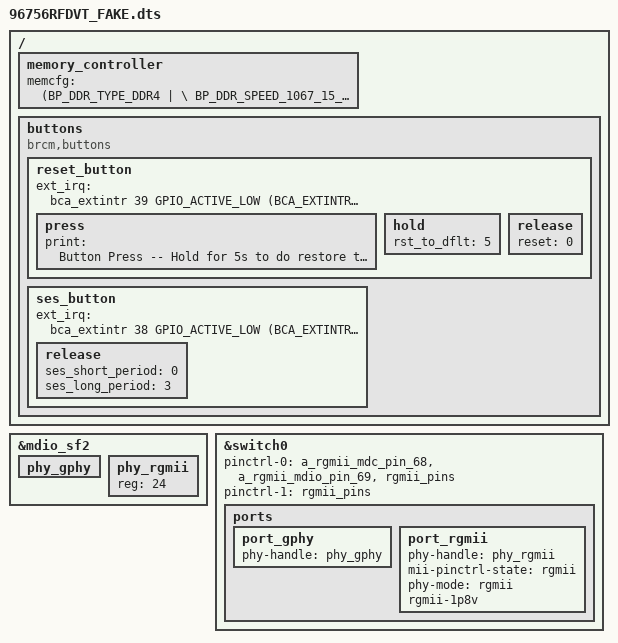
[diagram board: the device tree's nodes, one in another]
#include "6756.dtsi"

/ {
	memory_controller {
		memcfg = <(BP_DDR_TYPE_DDR4           | \
			BP_DDR_SPEED_1067_15_15_15 | \
			BP_DDR_TOTAL_SIZE_2048MB   | \
			BP_DDR_DEVICE_WIDTH_8      | \
			BP_DDR_TOTAL_WIDTH_16BIT   | \
			BP_DDR_6756_DEFAULT          | \
			BP_DDR_CONFIG_DEBUG)>;
	};

	buttons {
		compatible = "brcm,buttons";
		reset_button {
			ext_irq = <&bca_extintr 39 GPIO_ACTIVE_LOW (BCA_EXTINTR_TYPE_LOW_LEVEL | BCA_EXTINTR_TYPE_SENSE_EDGE)>;
			press {
				print = "Button Press -- Hold for 5s to do restore to default";
			};
			hold {
				rst_to_dflt = <5>;
			};
			release {
				reset = <0>;
			};	
		};
		ses_button {
			ext_irq = <&bca_extintr 38 GPIO_ACTIVE_LOW (BCA_EXTINTR_TYPE_LOW_LEVEL | BCA_EXTINTR_TYPE_SENSE_EDGE)>;
			release {
				ses_short_period = <0>;
				ses_long_period = <3>;
			};
		};	
	};
};


&mdio_sf2 {
   /* Port PHY mapping:
        port_imp -8#0- port_gphy <---> phy_gphy
                  ##1- port_rgmii <--> phy_rgmii
     */
	phy_gphy {
		status = "okay";
	};
	phy_rgmii {
		reg = <24>;
		status = "okay";
	};
};

&switch0 {
	pinctrl-names = "default", "rgmii"; 
	pinctrl-0 = <&a_rgmii_mdc_pin_68 &a_rgmii_mdio_pin_69 &rgmii_pins>; 
	pinctrl-1 = <&rgmii_pins>; 

	ports {
		port_gphy {
			phy-handle = <&phy_gphy>;
			status = "okay";
		};
		port_rgmii {
			phy-handle = <&phy_rgmii>;
			mii-pinctrl-state = "rgmii";
			phy-mode = "rgmii";
			rgmii-1p8v;
			status = "okay";
		};		
	};
};

